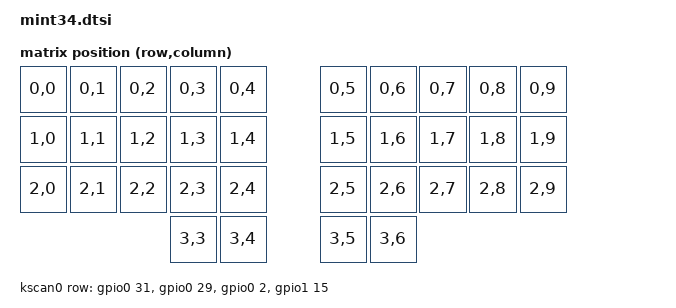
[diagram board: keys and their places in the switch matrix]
/*
 * Mint34 - Shared matrix definition
 * 34 key split: 5 cols x 3 rows + 2 thumb keys per side
 * Diodes: Col to Row (cathode toward row)
 *
 * Pin assignments (Pro Micro NRF52840):
 * Rows: P0.31, P0.29, P0.02, P1.15
 * Cols: P0.17, P0.20, P0.22, P0.24, P1.00
 *
 * Key positions:
 *  0  1  2  3  4    5  6  7  8  9
 * 10 11 12 13 14   15 16 17 18 19
 * 20 21 22 23 24   25 26 27 28 29
 *             30 31   32 33
 */

#include <dt-bindings/zmk/matrix_transform.h>

/ {
    chosen {
        zmk,kscan = &kscan0;
        zmk,matrix_transform = &default_transform;
    };

    default_transform: keymap_transform_0 {
        compatible = "zmk,matrix-transform";
        columns = <10>;
        rows = <4>;

        /*
         * Left half cols  0-4, right half cols 5-9
         * Thumbs at R3: left = C3,C4 / right = C5,C6
         *
         * Row 0: Q  W  E  R  T  |  Y  U  I  O  P
         * Row 1: A  S  D  F  G  |  H  J  K  L  ;
         * Row 2: Z  X  C  V  B  |  N  M  ,  .  /
         * Row 3:       ENT SYM  | SPC BSP
         */
        map = <
            RC(0,0) RC(0,1) RC(0,2) RC(0,3) RC(0,4)    RC(0,5) RC(0,6) RC(0,7) RC(0,8) RC(0,9)
            RC(1,0) RC(1,1) RC(1,2) RC(1,3) RC(1,4)    RC(1,5) RC(1,6) RC(1,7) RC(1,8) RC(1,9)
            RC(2,0) RC(2,1) RC(2,2) RC(2,3) RC(2,4)    RC(2,5) RC(2,6) RC(2,7) RC(2,8) RC(2,9)
                                    RC(3,3) RC(3,4)    RC(3,5) RC(3,6)
        >;
    };

    kscan0: kscan {
        compatible = "zmk,kscan-gpio-matrix";
        label = "KSCAN";
        diode-direction = "col2row";

        row-gpios
            = <&gpio0 31 (GPIO_ACTIVE_HIGH | GPIO_PULL_DOWN)>
            , <&gpio0 29 (GPIO_ACTIVE_HIGH | GPIO_PULL_DOWN)>
            , <&gpio0 2  (GPIO_ACTIVE_HIGH | GPIO_PULL_DOWN)>
            , <&gpio1 15 (GPIO_ACTIVE_HIGH | GPIO_PULL_DOWN)>
            ;
    };
};


/*

// This file was generated from a template. Edit it to match your keyboard.
// See https://zmk.dev/docs/development/hardware-integration/new-shield for more
// instructions.

#include <dt-bindings/zmk/matrix_transform.h>

#include "mint34-layouts.dtsi"

/ {
    chosen {
        zmk,physical-layout = &default_layout;
    };

    kscan: kscan {
        // If the hardware does not use a switch matrix, change this to the
        // appropriate driver and update the properties below to match.
        // See https://zmk.dev/docs/config/kscan for supported key scan drivers.
        compatible = "zmk,kscan-gpio-matrix";
        // Set this to "col2row" or "row2col" to match the hardware. If using
        // "row2col", change the col-gpios in the _left.overlay and _right.overlay
        // files to (GPIO_ACTIVE_HIGH | GPIO_PULL_DOWN) and the row-gpios here to
        // GPIO_ACTIVE_HIGH.
        diode-direction = "col2row";
        wakeup-source;

        // Replace these comments with the GPIO pins in the matrix.
        // See https://zmk.dev/docs/development/hardware-integration/new-shield#shield-overlays
        row-gpios
            = <&pro_micro 0 (GPIO_ACTIVE_HIGH | GPIO_PULL_DOWN)>
            , <&pro_micro 0 (GPIO_ACTIVE_HIGH | GPIO_PULL_DOWN)>
            ;
    };

    default_transform: default_transform {
        // See https://zmk.dev/docs/development/hardware-integration/new-shield#matrix-transform
        // for how to configure this
        compatible = "zmk,matrix-transform";
        columns = <4>;
        rows = <2>;

        map = <
            RC(0, 0) RC(0, 1)    RC(0, 2) RC(0, 3)
            RC(1, 0) RC(1, 1)    RC(1, 2) RC(1, 3)
        >;
    };
};
*/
